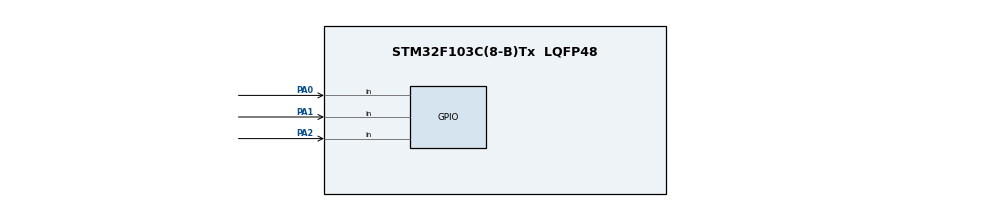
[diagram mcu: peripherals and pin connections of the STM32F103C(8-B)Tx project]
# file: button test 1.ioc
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Mcu.Family=STM32F1
Mcu.Name=STM32F103C(8-B)Tx
Mcu.Package=LQFP48
NVIC.PriorityGroup=NVIC_PRIORITYGROUP_4
PA0-WKUP.GPIO_PuPd=GPIO_PULLUP
PA0-WKUP.Signal=GPIO_Input
PA1.GPIO_PuPd=GPIO_PULLUP
PA1.Signal=GPIO_Input
PA13.Mode=Serial_Wire
PA13.Signal=SYS_JTMS-SWDIO
PA14.Mode=Serial_Wire
PA14.Signal=SYS_JTCK-SWCLK
PA2.GPIO_PuPd=GPIO_PULLUP
PA2.Signal=GPIO_Input
PD0-OSC_IN.Mode=HSE-External-Oscillator
PD0-OSC_IN.Signal=RCC_OSC_IN
PD1-OSC_OUT.Mode=HSE-External-Oscillator
PD1-OSC_OUT.Signal=RCC_OSC_OUT
ProjectManager.HeapSize=0x200
ProjectManager.StackSize=0x400
ProjectManager.TargetToolchain=STM32CubeIDE
RCC.APB1Freq_Value=8000000
RCC.APB2Freq_Value=8000000
board=custom

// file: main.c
/* USER CODE BEGIN Header */
/**
  ******************************************************************************
  * @file           : main.c
  * @brief          : Main program body
  ******************************************************************************
  * @attention
  *
  * Copyright (c) 2023 STMicroelectronics.
  * All rights reserved.
  *
  * This software is licensed under terms that can be found in the LICENSE file
  * in the root directory of this software component.
  * If no LICENSE file comes with this software, it is provided AS-IS.
  *
  ******************************************************************************
  */
/* USER CODE END Header */
#include "main.h"

/* USER CODE BEGIN Includes */
#include "button.h"
/* USER CODE END Includes */

/* USER CODE BEGIN PV */
//int count1 = 0;
//int count2 = 0;
//float temp;
/* USER CODE END PV */

void SystemClock_Config(void);
static void MX_GPIO_Init(void);

/* USER CODE BEGIN 0 */
int count1 = 0;
int count2 = 0;
float temp;
Button_TypeDef buttonmode;
Button_TypeDef buttonup;
Button_TypeDef buttondown;
Button_TypeDef *ButtonX;
//int count1 = 0;
//int count2 = 0;
//float temp;

//uint8_t count1 = 0;
//uint8_t count2 = 0;
void btn_adjust_down(void);
void btn_adjust_up(void);
typedef enum
{
	BINHTHUONG = 0,
	CHINHPHUT = 1,
	CHINHGIO = 2,
//	CHINHNGAY = 3,
}Mode;

Mode mode;

void btn_pressing_callback(GPIO_TypeDef *GPIOx, uint16_t GPIO_Pin)
{
	if ((GPIOx == GPIOA) && (ButtonX->GPIO_Pin == GPIO_PIN_0))
	{
		switch (mode)
		{
	case BINHTHUONG:
		mode = CHINHPHUT;
		break;
	case CHINHPHUT:
		mode = CHINHGIO;
		break;
//	case CHINHGIO:
//		mode = CHINHNGAY;
//		break;
//	case CHINHNGAY:
//		mode = BINHTHUONG;
//		break;
		}
	}
	if ((GPIOx == GPIOA) && (ButtonX->GPIO_Pin == GPIO_PIN_1))
		{
		btn_adjust_up();
		}
	if ((GPIOx == GPIOA) && (ButtonX->GPIO_Pin == GPIO_PIN_2))
		{
		btn_adjust_down();
		}
}
	void btn_adjust_up(void)
	{
	switch(mode)
		{
		case CHINHPHUT:
			count1++;
			break;
		case CHINHGIO:
			count2++;
			break;
//		case CHINHNGAY:
//			// viet code de cong 1 ngay va biet duoc so ngay trong thang de quay lai
//			break;
		}
	}
	void btn_adjust_down(void)
	{
		switch (mode)
		{
		case CHINHPHUT:
			count1--;
			break;
		case CHINHGIO:
			count2--;
			break;
//		case CHINHNGAY:
//			// viet code de tru 1 ngay va khi den 0 thi quay lai
//		break;
		}
	}

/* USER CODE END 0 */

int main(void)
{

  /* MCU Configuration--------------------------------------------------------*/

  /* Reset of all peripherals, Initializes the Flash interface and the Systick. */
  HAL_Init();

  /* Configure the system clock */
  SystemClock_Config();

  /* Initialize all configured peripherals */
  MX_GPIO_Init();
  /* USER CODE BEGIN 2 */
button_init(&buttonmode, GPIOA, GPIO_PIN_0);
button_init(&buttonup, GPIOA, GPIO_PIN_1);
button_init(&buttondown, GPIOA, GPIO_PIN_2);

  /* USER CODE END 2 */

  /* Infinite loop */
   while (1){

    /* USER CODE BEGIN 3 */
	button_handle(&buttonmode);
	button_handle(&buttonup);
	button_handle(&buttondown);
}
}
  /* USER CODE END 3 */

void SystemClock_Config(void)
{
  RCC_OscInitTypeDef RCC_OscInitStruct = {0};
  RCC_ClkInitTypeDef RCC_ClkInitStruct = {0};

  /** Initializes the RCC Oscillators according to the specified parameters
  * in the RCC_OscInitTypeDef structure.
  */
  RCC_OscInitStruct.OscillatorType = RCC_OSCILLATORTYPE_HSI;
  RCC_OscInitStruct.HSIState = RCC_HSI_ON;
  RCC_OscInitStruct.HSICalibrationValue = RCC_HSICALIBRATION_DEFAULT;
  RCC_OscInitStruct.PLL.PLLState = RCC_PLL_NONE;
  if (HAL_RCC_OscConfig(&RCC_OscInitStruct) != HAL_OK)
  {
    Error_Handler();
  }

  /** Initializes the CPU, AHB and APB buses clocks
  */
  RCC_ClkInitStruct.ClockType = RCC_CLOCKTYPE_HCLK|RCC_CLOCKTYPE_SYSCLK
                              |RCC_CLOCKTYPE_PCLK1|RCC_CLOCKTYPE_PCLK2;
  RCC_ClkInitStruct.SYSCLKSource = RCC_SYSCLKSOURCE_HSI;
  RCC_ClkInitStruct.AHBCLKDivider = RCC_SYSCLK_DIV1;
  RCC_ClkInitStruct.APB1CLKDivider = RCC_HCLK_DIV1;
  RCC_ClkInitStruct.APB2CLKDivider = RCC_HCLK_DIV1;

  if (HAL_RCC_ClockConfig(&RCC_ClkInitStruct, FLASH_LATENCY_0) != HAL_OK)
  {
    Error_Handler();
  }
}

static void MX_GPIO_Init(void)
{
  GPIO_InitTypeDef GPIO_InitStruct = {0};

  /* GPIO Ports Clock Enable */
  __HAL_RCC_GPIOD_CLK_ENABLE();
  __HAL_RCC_GPIOA_CLK_ENABLE();

  /*Configure GPIO pins : PA0 PA1 PA2 */
  GPIO_InitStruct.Pin = GPIO_PIN_0|GPIO_PIN_1|GPIO_PIN_2;
  GPIO_InitStruct.Mode = GPIO_MODE_INPUT;
  GPIO_InitStruct.Pull = GPIO_PULLUP;
  HAL_GPIO_Init(GPIOA, &GPIO_InitStruct);

}

void Error_Handler(void)
{
  __disable_irq();
  while (1)
  {
  }
}
